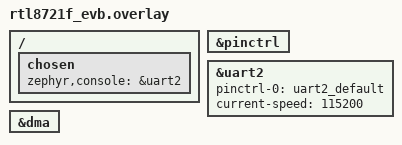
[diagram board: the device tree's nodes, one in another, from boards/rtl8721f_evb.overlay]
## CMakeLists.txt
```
# SPDX-License-Identifier: Apache-2.0

cmake_minimum_required(VERSION 3.28.0)
find_package(Zephyr REQUIRED HINTS $ENV{ZEPHYR_BASE})
project(uart_basic_api)

target_sources(app PRIVATE
    src/main.c
    src/test_uart_config.c
    src/test_uart_poll.c
    )
target_sources_ifdef(CONFIG_UART_INTERRUPT_DRIVEN app PRIVATE src/test_uart_fifo.c)
target_sources_ifdef(CONFIG_UART_INTERRUPT_DRIVEN app PRIVATE src/test_uart_pending.c)
target_sources_ifdef(CONFIG_UART_WIDE_DATA app PRIVATE src/test_uart_config_wide.c)
```

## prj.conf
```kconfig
CONFIG_SERIAL=y
CONFIG_UART_INTERRUPT_DRIVEN=y
CONFIG_UART_USE_RUNTIME_CONFIGURE=y
CONFIG_ZTEST=y
CONFIG_UART_NATIVE_PTY_0_ON_STDINOUT=y
```

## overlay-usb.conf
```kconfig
CONFIG_USB_DEVICE_STACK_NEXT=y
CONFIG_CDC_ACM_SERIAL_INITIALIZE_AT_BOOT=y
CONFIG_CDC_ACM_SERIAL_PRODUCT_STRING="Zephyr CDC ACM UART"
CONFIG_UART_LINE_CTRL=y
CONFIG_TEST_LOGGING_DEFAULTS=n
```

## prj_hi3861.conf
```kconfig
# SPDX-FileCopyrightText: Copyright The Zephyr Project Contributors
# SPDX-License-Identifier: Apache-2.0

CONFIG_SERIAL=y
CONFIG_UART_INTERRUPT_DRIVEN=y
CONFIG_UART_USE_RUNTIME_CONFIGURE=y
CONFIG_ZTEST=y
```

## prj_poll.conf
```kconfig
CONFIG_SERIAL=y
CONFIG_UART_USE_RUNTIME_CONFIGURE=y
CONFIG_ZTEST=y
CONFIG_UART_NATIVE_PTY_0_ON_STDINOUT=y
```

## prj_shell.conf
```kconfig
CONFIG_SERIAL=y
CONFIG_UART_INTERRUPT_DRIVEN=y
CONFIG_UART_USE_RUNTIME_CONFIGURE=y
CONFIG_ZTEST=y
CONFIG_SHELL_CMD_BUFF_SIZE=90
CONFIG_SHELL=y
CONFIG_UART_NATIVE_PTY_0_ON_STDINOUT=y
```

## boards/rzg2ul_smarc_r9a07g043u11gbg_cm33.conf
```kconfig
# Enable UART console
CONFIG_UART_CONSOLE=y
```

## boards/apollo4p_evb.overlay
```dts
/*
 * SPDX-License-Identifier: Apache-2.0
 */

/ {

	aliases {
		dut = &uart0;
	};
};
```

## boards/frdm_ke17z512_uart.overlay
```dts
/*
 * Copyright 2024 NXP
 * SPDX-License-Identifier: Apache-2.0
 */

/ {
	chosen {
		zephyr,shell-uart = &uart1;
	};
};

/* This configuration is to test "UART" driver
 * UART1_RX_PTC16(J4->10)
 * UART1_TX_PTC17(J4->12)
 */

&uart1 {
	pinctrl-0 = <&uart1_default>;
	pinctrl-names = "default";
	current-speed = <115200>;
	status = "okay";
};
```

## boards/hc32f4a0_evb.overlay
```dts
/*
 * SPDX-License-Identifier: Apache-2.0
 */

dut: &usart1 {
	pinctrl-0 = <&usart1_default>;
	pinctrl-names = "default";
	current-speed = <115200>;
	status = "okay";
};

&usart2 {
	status = "okay";
	current-speed = <115200>;
	pinctrl-0 = <&usart2_default>;
	pinctrl-names = "default";
	/delete-property/ interrupts;
	/delete-property/ interrupt-names;
};
```

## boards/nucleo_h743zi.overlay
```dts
/*
 * SPDX-License-Identifier: Apache-2.0
 */

dut: &usart2 {
	pinctrl-0 = <&usart2_tx_pd5 &usart2_rx_pd6>;
	pinctrl-names = "default";
	current-speed = <115200>;
	status = "okay";
};
```

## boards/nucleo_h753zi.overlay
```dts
/*
 * Copyright (c) 2025 STMicroelectronics
 *
 * SPDX-License-Identifier: Apache-2.0
 */

dut: &usart2 {
	pinctrl-0 = <&usart2_tx_pd5 &usart2_rx_pd6>;
	pinctrl-names = "default";
	current-speed = <115200>;
	status = "okay";
};
```

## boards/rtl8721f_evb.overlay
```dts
/*
 * Copyright (c) 2026 Realtek Semiconductor Corp.
 *
 * SPDX-License-Identifier: Apache-2.0
 */

/ {
	chosen {
		zephyr,console = &uart2;
	};
};

/*
 * UART2_TX -> PA25 <-> FT232 RX
 * UART2_RX -> PA26 <-> FT232 TX
 */

&pinctrl {
	status = "okay";
};

&uart2 {
	pinctrl-0 = <&uart2_default>;
	pinctrl-names = "default";
	current-speed = <115200>;
	status = "okay";
};

&dma {
	status = "okay";
};
```

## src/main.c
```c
/*
 * Copyright (c) 2016 Intel Corporation
 *
 * SPDX-License-Identifier: Apache-2.0
 */

/**
 * @addtogroup t_driver_uart
 * @{
 * @defgroup t_uart_basic test_uart_basic_operations
 * @}
 */

#include "test_uart.h"

#ifdef CONFIG_SHELL
TC_CMD_DEFINE(test_uart_configure)
TC_CMD_DEFINE(test_uart_config_get)
TC_CMD_DEFINE(test_uart_poll_out)
TC_CMD_DEFINE(test_uart_poll_out_blocking)
TC_CMD_DEFINE(test_uart_poll_in)
#if CONFIG_UART_INTERRUPT_DRIVEN
TC_CMD_DEFINE(test_uart_fifo_read)
TC_CMD_DEFINE(test_uart_fifo_fill)
TC_CMD_DEFINE(test_uart_pending)
#endif

SHELL_CMD_REGISTER(test_uart_configure, NULL, NULL,
			TC_CMD_ITEM(test_uart_configure));
SHELL_CMD_REGISTER(test_uart_config_get, NULL, NULL,
			TC_CMD_ITEM(test_uart_config_get));
SHELL_CMD_REGISTER(test_uart_poll_in, NULL, NULL,
			TC_CMD_ITEM(test_uart_poll_in));
SHELL_CMD_REGISTER(test_uart_poll_out, NULL, NULL,
			TC_CMD_ITEM(test_uart_poll_out));
SHELL_CMD_REGISTER(test_uart_poll_out_blocking, NULL, NULL,
			TC_CMD_ITEM(test_uart_poll_out_blocking));
#if CONFIG_UART_INTERRUPT_DRIVEN
SHELL_CMD_REGISTER(test_uart_fifo_read, NULL, NULL,
			TC_CMD_ITEM(test_uart_fifo_read));
SHELL_CMD_REGISTER(test_uart_fifo_fill, NULL, NULL,
			TC_CMD_ITEM(test_uart_fifo_fill));
SHELL_CMD_REGISTER(test_uart_pending, NULL, NULL,
			TC_CMD_ITEM(test_uart_pending));
#endif


#endif

void *uart_basic_setup(void)
{
#if DT_NODE_HAS_COMPAT(DT_CHOSEN(zephyr_console), zephyr_cdc_acm_uart)
	const struct device *dev;
	uint32_t dtr = 0;

	dev = DEVICE_DT_GET(DT_CHOSEN(zephyr_console));
	if (!device_is_ready(dev)) {
		return NULL;
	}

	while (!dtr) {
		uart_line_ctrl_get(dev, UART_LINE_CTRL_DTR, &dtr);
		k_sleep(K_MSEC(100));
	}
#endif
	return NULL;
}

#ifndef CONFIG_SHELL
ZTEST_SUITE(uart_basic_api, NULL, uart_basic_setup, NULL, NULL, NULL);

/* The UART pending test should be test finally. */
ZTEST_SUITE(uart_basic_api_pending, NULL, uart_basic_setup, NULL, NULL, NULL);
#endif
```

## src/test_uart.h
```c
/*
 * Copyright (c) 2016 Intel Corporation
 * Copyright (c) 2020 Intel Corporation
 *
 * SPDX-License-Identifier: Apache-2.0
 */

/**
 * @file
 * @brief UART cases header file
 *
 * Header file for UART cases
 */

#ifndef __TEST_UART_H__
#define __TEST_UART_H__

#include <zephyr/drivers/uart.h>
#include <zephyr/ztest.h>

#if CONFIG_SHELL
void test_uart_configure(void);
void test_uart_config_get(void);
void test_uart_poll_out(void);
void test_uart_poll_out_blocking(void);
void test_uart_poll_in(void);
#if CONFIG_UART_WIDE_DATA
void test_uart_configure_wide(void);
void test_uart_config_get_wide(void);
#endif
#if CONFIG_UART_INTERRUPT_DRIVEN
void test_uart_fifo_fill(void);
void test_uart_fifo_read(void);
void test_uart_pending(void);
#endif

#endif

#endif /* __TEST_UART_H__ */
```

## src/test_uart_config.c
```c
/*
 * Copyright (c) 2020 Intel Corporation
 *
 * SPDX-License-Identifier: Apache-2.0
 */

/*
 * @addtogroup t_uart_basic
 * @{
 * @defgroup t_uart_config test_uart_config
 * @brief TestPurpose: verify UART configure API settings
 * @details
 * - Test Steps
 *   - Configure: test_uart_configure( )
 *   - Configure Get: test_uart_config_get( )
 * - Expected Results
 *   -# When test UART CONFIG Configure, the value of configurations actually
 *      set will be equal to the original configuration values (from device
 *      tree or run-time configuration to modify those loaded initially from
 *      device tree)
 *   -# When test UART CONFIG Configure Get, the app will get/retrieve the
 *      value of configurations stored at location and to be passed to UART
 *      CONFIG Configure
 * @}
 */

#include "test_uart.h"
const struct uart_config uart_cfg = {
		.baudrate = DT_PROP_OR(DT_CHOSEN(zephyr_console), current_speed, 115200),
		.parity = UART_CFG_PARITY_NONE,
		.stop_bits = UART_CFG_STOP_BITS_1,
		.data_bits = UART_CFG_DATA_BITS_8,
		.flow_ctrl = UART_CFG_FLOW_CTRL_NONE
	};

static int test_configure(void)
{
	const struct device *const uart_dev = DEVICE_DT_GET(DT_CHOSEN(zephyr_console));

	if (!device_is_ready(uart_dev)) {
		TC_PRINT("UART device not ready\n");
		return TC_FAIL;
	}

	/* Verify configure() - set device configuration using data in cfg */
	int ret = uart_configure(uart_dev, &uart_cfg);

	if (ret == -ENOSYS) {
		return TC_SKIP;
	}

	/* 0 if successful, - error code otherwise */
	return (ret == 0) ? TC_PASS : TC_FAIL;

}

/* test UART configure get (retrieve configuration) */
static int test_config_get(void)
{
	struct uart_config uart_cfg_check;
	const struct device *const uart_dev = DEVICE_DT_GET(DT_CHOSEN(zephyr_console));

	if (!device_is_ready(uart_dev)) {
		TC_PRINT("UART device not ready\n");
		return TC_FAIL;
	}

	TC_PRINT("This is a configure_get test.\n");

	/* Verify configure() - set device configuration using data in cfg */
	/* 0 if successful, - error code otherwise */
	int ret = uart_configure(uart_dev, &uart_cfg);

	if (ret == -ENOSYS) {
		return TC_SKIP;
	}

	zassert_true(ret == 0, "set config error");

	/* Verify config_get() - get device configuration, put in cfg */
	/* 0 if successful, - error code otherwise */
	/* so get the configurations from the device and check */
	ret = uart_config_get(uart_dev, &uart_cfg_check);
	zassert_true(ret == 0, "get config error");

	/* Confirm the values from device are the values put in cfg*/
	if (memcmp(&uart_cfg, &uart_cfg_check, sizeof(uart_cfg)) != 0) {
		return TC_FAIL;
	} else {
		return TC_PASS;
	}
}

#if CONFIG_SHELL
void test_uart_configure(void)
#else
ZTEST(uart_basic_api, test_uart_configure)
#endif
{
	int ret = test_configure();

	zassert_true((ret == TC_PASS) || (ret == TC_SKIP));
}

#if CONFIG_SHELL
void test_uart_config_get(void)
#else
ZTEST(uart_basic_api, test_uart_config_get)
#endif
{
	int ret = test_config_get();

	zassert_true((ret == TC_PASS) || (ret == TC_SKIP));
}
```

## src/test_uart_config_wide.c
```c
/*
 * Copyright (c) 2023 Jeroen van Dooren
 *
 * SPDX-License-Identifier: Apache-2.0
 */

/*
 * @addtogroup t_uart_basic
 * @{
 * @defgroup t_uart_config_wide test_uart_config_wide
 * @brief TestPurpose: verify UART configure API settings for wide data support
 * @details
 * - Test Steps
 *   - Configure: test_uart_configure_wide( )
 *   - Configure Get: test_uart_config_get_wide( )
 * - Expected Results
 *   -# When test UART CONFIG Configure, the value of configurations actually
 *      set will be equal to the original configuration values (from device
 *      tree or run-time configuration to modify those loaded initially from
 *      device tree)
 *   -# When test UART CONFIG Configure Get, the app will get/retrieve the
 *      value of configurations stored at location and to be passed to UART
 *      CONFIG Configure
 * @}
 */

#include "test_uart.h"
const struct uart_config uart_cfg_wide = {
		.baudrate = DT_PROP_OR(DT_NODELABEL(dut), current_speed, 115200),
		.parity = UART_CFG_PARITY_NONE,
		.stop_bits = UART_CFG_STOP_BITS_1,
		.data_bits = UART_CFG_DATA_BITS_9,
		.flow_ctrl = UART_CFG_FLOW_CTRL_NONE
	};

static int test_configure_wide(void)
{
	const struct device *const uart_dev = DEVICE_DT_GET(DT_NODELABEL(dut));

	if (!device_is_ready(uart_dev)) {
		TC_PRINT("UART device not ready\n");
		return TC_FAIL;
	}

	/* Verify configure() - set device configuration using data in cfg */
	int ret = uart_configure(uart_dev, &uart_cfg_wide);

	if (ret == -ENOSYS) {
		return TC_SKIP;
	}

	/* 0 if successful, - error code otherwise */
	return (ret == 0) ? TC_PASS : TC_FAIL;

}

/* test UART configure get (retrieve configuration) */
static int test_config_get_wide(void)
{
	struct uart_config uart_cfg_check;
	const struct device *const uart_dev = DEVICE_DT_GET(DT_NODELABEL(dut));

	if (!device_is_ready(uart_dev)) {
		TC_PRINT("UART device not ready\n");
		return TC_FAIL;
	}

	TC_PRINT("This is a configure_get_wide test.\n");

	/* Verify configure() - set device configuration using data in cfg */
	/* 0 if successful, - error code otherwise */
	int ret = uart_configure(uart_dev, &uart_cfg_wide);

	if (ret == -ENOSYS) {
		return TC_SKIP;
	}

	zassert_true(ret == 0, "set config error");

	/* Verify config_get() - get device configuration, put in cfg */
	/* 0 if successful, - error code otherwise */
	/* so get the configurations from the device and check */
	ret = uart_config_get(uart_dev, &uart_cfg_check);
	zassert_true(ret == 0, "get config error");

	/* Confirm the values from device are the values put in cfg*/
	if (memcmp(&uart_cfg_wide, &uart_cfg_check, sizeof(uart_cfg_wide)) != 0) {
		return TC_FAIL;
	} else {
		return TC_PASS;
	}
}

#if CONFIG_SHELL
void test_uart_configure_wide(void)
#else
ZTEST(uart_basic_api, test_uart_configure_wide)
#endif
{
	int ret = test_configure_wide();

	zassert_true((ret == TC_PASS) || (ret == TC_SKIP));
}

#if CONFIG_SHELL
void test_uart_config_get_wide(void)
#else
ZTEST(uart_basic_api, test_uart_config_get_wide)
#endif
{
	int ret = test_config_get_wide();

	zassert_true((ret == TC_PASS) || (ret == TC_SKIP));
}
```

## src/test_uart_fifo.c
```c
/*
 * Copyright (c) 2016 Intel Corporation
 *
 * SPDX-License-Identifier: Apache-2.0
 */

/*
 * @addtogroup t_uart_basic
 * @{
 * @defgroup t_uart_fifo test_uart_fifo
 * @brief TestPurpose: verify UART works well in fifo mode
 * @details
 * - Test Steps
 *   - FIFO Output:
 *      -# Set UART IRQ callback using uart_irq_callback_set().
 *      -# Enable UART TX IRQ using uart_irq_tx_enable().
 *      -# Output the prepared data using uart_fifo_fill().
 *      -# Disable UART TX IRQ using uart_irq_tx_disable().
 *      -# Compare the number of characters sent out with the
 *         original data size.
 *   - FIFO Input:
 *      -# Set UART IRQ callback using uart_irq_callback_set().
 *      -# Enable UART RX IRQ using uart_irq_rx_enable().
 *      -# Wait for data sent to UART console and trigger RX IRQ.
 *      -# Read data from UART console using uart_fifo_read().
 *      -# Disable UART TX IRQ using uart_irq_rx_disable().
 * - Expected Results
 *   -# When test UART FIFO output, the number of characters actually
 *      sent out will be equal to the original length of the characters.
 *   -# When test UART FIFO input, the app will wait for input from UART
 *      console and exit after receiving one character.
 * @}
 */

#include "test_uart.h"

static volatile bool data_transmitted;
static volatile bool data_received;
static int char_sent;
static const char fifo_data[] = "This is a FIFO test.\r\n";

#define DATA_SIZE	(sizeof(fifo_data) - 1)

static void uart_fifo_callback(const struct device *dev, void *user_data)
{
	uint8_t recvData;
	static int tx_data_idx;
	int ret;

	ARG_UNUSED(user_data);

	/* Verify uart_irq_update() */
	uart_irq_update(dev);

	/* Verify uart_irq_tx_ready() */
	/* Note that TX IRQ may be disabled, but uart_irq_tx_ready() may
	 * still return true when ISR is called for another UART interrupt,
	 * hence additional check for i < DATA_SIZE.
	 */
	if (uart_irq_tx_ready(dev) && tx_data_idx < DATA_SIZE) {
		/* We arrive here by "tx ready" interrupt, so should always
		 * be able to put at least one byte into a FIFO. If not,
		 * well, we'll fail test.
		 */
		ret = uart_fifo_fill(dev, (uint8_t *)&fifo_data[tx_data_idx],
				     DATA_SIZE - char_sent);
		if (ret > 0) {
			data_transmitted = true;
			char_sent += ret;
			tx_data_idx += ret;
		} else {
			uart_irq_tx_disable(dev);
			return;
		}

		if (tx_data_idx == DATA_SIZE) {
			/* If we transmitted everything, stop IRQ stream,
			 * otherwise main app might never run.
			 */
			uart_irq_tx_disable(dev);
		}
	}

	/* Verify uart_irq_rx_ready() */
	if (uart_irq_rx_ready(dev)) {
		/* Verify uart_fifo_read() */
		uart_fifo_read(dev, &recvData, 1);
		TC_PRINT("%c", recvData);

		if ((recvData == '\n') || (recvData == '\r')) {
			data_received = true;
		}
	}
}

static int test_fifo_read(void)
{
	const struct device *const uart_dev = DEVICE_DT_GET(DT_CHOSEN(zephyr_console));

	if (!device_is_ready(uart_dev)) {
		TC_PRINT("UART device not ready\n");
		return TC_FAIL;
	}

	/* Verify uart_irq_callback_set() */
	uart_irq_callback_set(uart_dev, uart_fifo_callback);

	/* Enable Tx/Rx interrupt before using fifo */
	/* Verify uart_irq_rx_enable() */
	uart_irq_rx_enable(uart_dev);

	TC_PRINT("Please send characters to serial console\n");

	data_received = false;
	while (data_received == false) {
		/* Allow other thread/workqueue to work. */
		k_yield();
	}

	/* Verify uart_irq_rx_disable() */
	uart_irq_rx_disable(uart_dev);

	return TC_PASS;
}

static int test_fifo_fill(void)
{
	const struct device *const uart_dev = DEVICE_DT_GET(DT_CHOSEN(zephyr_console));

	if (!device_is_ready(uart_dev)) {
		TC_PRINT("UART device not ready\n");
		return TC_FAIL;
	}

	char_sent = 0;

	/* Verify uart_irq_callback_set() */
	uart_irq_callback_set(uart_dev, uart_fifo_callback);

	/* Enable Tx/Rx interrupt before using fifo */
	/* Verify uart_irq_tx_enable() */
	uart_irq_tx_enable(uart_dev);

	k_sleep(K_MSEC(500));

	/* Verify uart_irq_tx_disable() */
	uart_irq_tx_disable(uart_dev);

	if (!data_transmitted) {
		return TC_FAIL;
	}

	if (char_sent == DATA_SIZE) {
		return TC_PASS;
	} else {
		return TC_FAIL;
	}

}

#if CONFIG_SHELL
void test_uart_fifo_fill(void)
#else
ZTEST(uart_basic_api, test_uart_fifo_fill)
#endif
{
#ifndef CONFIG_UART_INTERRUPT_DRIVEN
	ztest_test_skip();
#endif
	zassert_true(test_fifo_fill() == TC_PASS);
}

#if CONFIG_SHELL
void test_uart_fifo_read(void)
#else
ZTEST(uart_basic_api, test_uart_fifo_read)
#endif
{
#ifndef CONFIG_UART_INTERRUPT_DRIVEN
	ztest_test_skip();
#endif
	zassert_true(test_fifo_read() == TC_PASS);
}
```

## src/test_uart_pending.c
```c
/*
 * Copyright (c) 2021 Linaro Limited
 *
 * SPDX-License-Identifier: Apache-2.0
 */

/*
 * @addtogroup t_uart_basic
 * @{
 * @defgroup t_uart_pending test_uart_pending
 * @brief TestPurpose: test UART uart_irq_is_pending()
 * @details
 *
 * Test if uart_irq_is_pending() correctly returns 0 when there are no
 * more RX and TX pending interrupts.
 *
 * The test consists in disabling TX IRQ so no TX interrupts are
 * generated and the TX IRQ pending flag is never set. At the same time
 * RX IRQ is enabled to let received data cause a RX IRQ and so set the
 * RX IRQ pending flag.
 *
 * Then a message is sent via serial to inform that the test is ready to
 * receive serial data, which will trigger a RX IRQ.
 *
 * Once a RX IRQ happens RX data is read by uart_fifo_read() until there
 * is no more RX data to be popped from FIFO and all IRQs are handled.
 * When that happens uart_irq_is_pending() is called and must return 0,
 * indicating there are no more pending interrupts to be processed. If 0
 * is returned the test passes.
 *
 * In some cases uart_irq_is_pending() does not correctly use the IRQ
 * pending flags to determine if there are pending interrupts, hence
 * even tho there aren't any further RX and TX IRQs to be processed it
 * wrongly returns 1. If 1 is returned the test fails.
 *
 * @}
 */

#include "test_uart.h"

#define MAX_NUM_TRIES 512
#define NOT_READY 0

#define FAILED	0
#define PASSED	1
#define WAIT	2
static int volatile status;

static void uart_pending_callback(const struct device *dev, void *user_data)
{
	ARG_UNUSED(user_data);

	int num_tries = 0;
	char recv_char;

	/*
	 * If the bug is not present uart_fifo_read() will pop all
	 * received data until there is no more RX data, thus
	 * uart_irq_is_pending() must correctly return 0 indicating
	 * that there are no more RX interrupts to be processed.
	 * Otherwise uart_irq_is_pending() never returns 0 even tho
	 * there is no more RX data in the RX buffer to be processed,
	 * so, in that case, the test fails after MAX_NUM_TRIES attempts.
	 */
	status = PASSED;
	while (true) {
		uart_irq_update(dev);

		if (uart_irq_is_pending(dev) <= 0) {
			break;
		}

		if (uart_irq_rx_ready(dev) == NOT_READY) {
			if (num_tries < MAX_NUM_TRIES) {
				num_tries++;
				continue;
			} else {
				/*
				 * Bug: no more tries; uart_irq_is_pending()
				 * always returned 1 in spite of having no more
				 * RX data to be read from FIFO and no more TX
				 * data in FIFO to be sent via serial line.
				 * uart_irq_is_pending() got stuck without any
				 * real pending interrupt, i.e. no more RX and
				 * TX data to be popped or pushed from/to FIFO.
				 */
				status = FAILED;
				break;
			}
		}

		while (uart_fifo_read(dev, &recv_char, 1)) {
			/* Echo received char */
			TC_PRINT("%c", recv_char);
		}
	}
}

static int test_pending(void)
{
	const struct device *const uart_dev = DEVICE_DT_GET(DT_CHOSEN(zephyr_console));

	if (!device_is_ready(uart_dev)) {
		TC_PRINT("UART device not ready\n");
		return TC_FAIL;
	}

	/*
	 * Set IRQ callback function to handle RX IRQ.
	 */
	uart_irq_callback_set(uart_dev, uart_pending_callback);

	/*
	 * Disable TX IRQ since transmitted data is not
	 * handled by uart_pending_callback() and we don't
	 * want to trigger any TX IRQ for this test.
	 */
	uart_irq_tx_disable(uart_dev);

	/*
	 * Enable RX IRQ so uart_pending_callback() can
	 * handle input data is available in RX FIFO.
	 */
	uart_irq_rx_enable(uart_dev);

	status = WAIT;

	/* Inform test is ready to receive data */
	TC_PRINT("Please send characters to serial console\n");

	while (status == WAIT) {
		/* Allow other thread/workqueue to work. */
		k_yield();
		/*
		 * Wait RX handler change 'status' properly:
		 * it will change to PASSED or FAILED after
		 * uart_irq_is_pending() is tested by
		 * uart_pending_callback() upon data reception.
		 */
	}

	if (status == PASSED) {
		return TC_PASS;
	} else {
		return TC_FAIL;
	}
}

#if CONFIG_SHELL
void test_uart_pending(void)
#else
ZTEST(uart_basic_api_pending, test_uart_pending)
#endif
{
#ifndef CONFIG_UART_INTERRUPT_DRIVEN
	ztest_test_skip();
#endif
	zassert_true(test_pending() == TC_PASS);
}
```

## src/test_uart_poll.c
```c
/*
 * Copyright (c) 2016 Intel Corporation
 *
 * SPDX-License-Identifier: Apache-2.0
 */

#include "test_uart.h"

static const char *poll_data = "This is a POLL test.\r\n";

static int test_poll_in(void)
{
	unsigned char recv_char;
	const struct device *const uart_dev = DEVICE_DT_GET(DT_CHOSEN(zephyr_console));

	if (!device_is_ready(uart_dev)) {
		TC_PRINT("UART device not ready\n");
		return TC_FAIL;
	}

	TC_PRINT("Please send characters to serial console\n");

	/* Verify uart_poll_in() */
	while (1) {
		while (uart_poll_in(uart_dev, &recv_char) < 0) {
			/* Allow other thread/workqueue to work. */
			k_yield();
		}

		TC_PRINT("%c", recv_char);

		if ((recv_char == '\n') || (recv_char == '\r')) {
			break;
		}
	}

	return TC_PASS;
}

static int test_poll_out(void)
{
	int i;
	const struct device *const uart_dev = DEVICE_DT_GET(DT_CHOSEN(zephyr_console));

	if (!device_is_ready(uart_dev)) {
		TC_PRINT("UART device not ready\n");
		return TC_FAIL;
	}

	/* Verify uart_poll_out() */
	for (i = 0; i < strlen(poll_data); i++) {
		uart_poll_out(uart_dev, poll_data[i]);
	}

	return TC_PASS;
}

static int test_poll_out_blocking(void)
{
	const struct device *const uart_dev = DEVICE_DT_GET(DT_CHOSEN(zephyr_console));
	struct uart_config cfg;
	uint32_t start_cycles, elapsed_cycles, elapsed_us;
	uint32_t expected_us, min_us;
	int err;

	if (!device_is_ready(uart_dev)) {
		TC_PRINT("UART device not ready\n");
		return TC_FAIL;
	}

	err = uart_config_get(uart_dev, &cfg);
	if (err < 0) {
		TC_PRINT("Failed to get UART config (%d)\n", err);
		return TC_FAIL;
	}
	k_sleep(K_MSEC(20));

	start_cycles = k_cycle_get_32();
	uart_poll_out(uart_dev, '#');
	elapsed_cycles = k_cycle_get_32() - start_cycles;
	elapsed_us = (uint32_t)k_cyc_to_us_floor32(elapsed_cycles);

	expected_us = (10U * 1000000U) / cfg.baudrate;
	min_us = (expected_us * 7U) / 10U;

	TC_PRINT("uart_poll_out took %u us (min expected %u us for %u baud)\n",
		 elapsed_us, min_us, cfg.baudrate);

	zassert_true(elapsed_us >= min_us,
		     "uart_poll_out did not block until character was sent. "
		     "Took %u us, expected >= %u us",
		     elapsed_us, min_us);

	return TC_PASS;
}

#if CONFIG_SHELL
void test_uart_poll_out_blocking(void)
#else
ZTEST(uart_basic_api, test_uart_poll_out_blocking)
#endif
{
	if (IS_ENABLED(CONFIG_UART_NRFX_UARTE) &&
	    !IS_ENABLED(CONFIG_UART_NRFX_UARTE_POLL_OUT_WAIT)) {
		ztest_test_skip();
	}

	zassert_true(test_poll_out_blocking() == TC_PASS);
}

#if CONFIG_SHELL
void test_uart_poll_out(void)
#else
ZTEST(uart_basic_api, test_uart_poll_out)
#endif
{
	zassert_true(test_poll_out() == TC_PASS);
}

#if CONFIG_SHELL
void test_uart_poll_in(void)
#else
ZTEST(uart_basic_api, test_uart_poll_in)
#endif
{
	zassert_true(test_poll_in() == TC_PASS);
}
```
